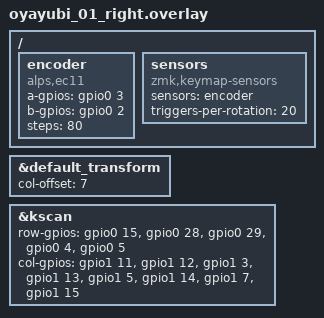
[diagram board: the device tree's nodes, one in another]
#include "oyayubi_01.dtsi"

// 右手 (peripheral) の GPIO アサイン
// ピン番号の出典: docs/xiao_gpio_map_v2.md
// &xiao_d は D11 以降未定義のため使わず、全ピン &gpio0/&gpio1 で直接指定

&default_transform {
    col-offset = <7>;  // 右 Col0 → unified col 7、右 Col7 → unified col 14
};

&kscan {
    row-gpios =
        <&gpio0 15 (GPIO_ACTIVE_HIGH | GPIO_PULL_DOWN)>,  // Row0 / D11 / P0.15
        <&gpio0 28 (GPIO_ACTIVE_HIGH | GPIO_PULL_DOWN)>,  // Row1 / D2  / P0.28
        <&gpio0 29 (GPIO_ACTIVE_HIGH | GPIO_PULL_DOWN)>,  // Row2 / D3  / P0.29
        <&gpio0 4  (GPIO_ACTIVE_HIGH | GPIO_PULL_DOWN)>,  // Row3 / D4  / P0.04
        <&gpio0 5  (GPIO_ACTIVE_HIGH | GPIO_PULL_DOWN)>;  // Row4 / D5  / P0.05

    col-gpios =
        <&gpio1 11 GPIO_ACTIVE_HIGH>,  // Col0 / D6  / P1.11
        <&gpio1 12 GPIO_ACTIVE_HIGH>,  // Col1 / D7  / P1.12
        <&gpio1 3  GPIO_ACTIVE_HIGH>,  // Col2 / D17 / P1.03  // TODO: 要実機検証（D17/D19 逆の可能性）
        <&gpio1 13 GPIO_ACTIVE_HIGH>,  // Col3 / D8  / P1.13
        <&gpio1 5  GPIO_ACTIVE_HIGH>,  // Col4 / D18 / P1.05
        <&gpio1 14 GPIO_ACTIVE_HIGH>,  // Col5 / D9  / P1.14
        <&gpio1 7  GPIO_ACTIVE_HIGH>,  // Col6 / D19 / P1.07  // TODO: 要実機検証（D17/D19 逆の可能性）
        <&gpio1 15 GPIO_ACTIVE_HIGH>;  // Col7 / D10 / P1.15
};

/ {
    // EC11 互換エンコーダ（ENC_A=D1/P0.03, ENC_B=D0/P0.02）
    // プッシュスイッチは Row2 × Col0 のマトリクスに入る（D38 経由）
    encoder: encoder {
        compatible = "alps,ec11";
        a-gpios = <&gpio0 3 (GPIO_ACTIVE_HIGH | GPIO_PULL_UP)>;  // ENC_A / D1 / P0.03
        b-gpios = <&gpio0 2 (GPIO_ACTIVE_HIGH | GPIO_PULL_UP)>;  // ENC_B / D0 / P0.02
        steps = <80>;  // 20 detents × 4 pulses/detent
    };

    // センサー登録（keymap の sensor-bindings と対応）
    sensors: sensors {
        compatible = "zmk,keymap-sensors";
        sensors = <&encoder>;
        triggers-per-rotation = <20>;  // 1 クリック = 1 イベント
    };
};
